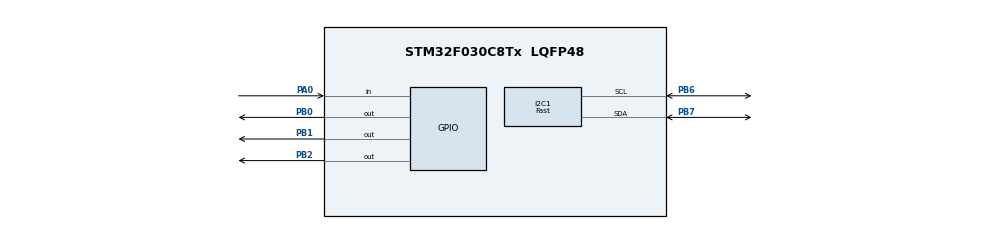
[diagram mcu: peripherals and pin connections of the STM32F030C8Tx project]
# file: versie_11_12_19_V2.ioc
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I2C1.I2C_Speed_Mode=I2C_Fast
I2C1.Timing=0x0000020B
Mcu.Family=STM32F0
Mcu.Name=STM32F030C8Tx
Mcu.Package=LQFP48
NVIC.TIM6_IRQn=true\:0\:0\:false\:false\:true\:true\:true
PA0.GPIO_PuPd=GPIO_PULLDOWN
PA0.Signal=GPIO_Input
PA13.Mode=Serial_Wire
PA13.Signal=SYS_SWDIO
PA14.Mode=Serial_Wire
PA14.Signal=SYS_SWCLK
PB0.GPIO_ModeDefaultOutputPP=GPIO_MODE_OUTPUT_PP
PB0.GPIO_PuPd=GPIO_NOPULL
PB0.GPIO_Speed=GPIO_SPEED_FREQ_LOW
PB0.PinState=GPIO_PIN_RESET
PB0.Signal=GPIO_Output
PB1.GPIO_ModeDefaultOutputPP=GPIO_MODE_OUTPUT_PP
PB1.GPIO_PuPd=GPIO_NOPULL
PB1.GPIO_Speed=GPIO_SPEED_FREQ_LOW
PB1.PinState=GPIO_PIN_RESET
PB1.Signal=GPIO_Output
PB2.GPIO_ModeDefaultOutputPP=GPIO_MODE_OUTPUT_PP
PB2.GPIO_PuPd=GPIO_NOPULL
PB2.GPIO_Speed=GPIO_SPEED_FREQ_LOW
PB2.PinState=GPIO_PIN_RESET
PB2.Signal=GPIO_Output
PB6.Mode=I2C
PB6.Signal=I2C1_SCL
PB7.Mode=I2C
PB7.Signal=I2C1_SDA
ProjectManager.HeapSize=0x200
ProjectManager.StackSize=0x400
ProjectManager.TargetToolchain=STM32CubeIDE
TIM6.Period=1000
TIM6.Prescaler=8000
VP_TIM6_VS_ClockSourceINT.Mode=Enable_Timer
board=custom

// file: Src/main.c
/* USER CODE BEGIN Header */
/**
  ******************************************************************************
  * @file           : main.c
  * @brief          : Main program body
  ******************************************************************************
  * @attention
  *
  * <h2><center>&copy; Copyright (c) 2019 STMicroelectronics.
  * All rights reserved.</center></h2>
  *
  * This software component is licensed by ST under BSD 3-Clause license,
  * the "License"; You may not use this file except in compliance with the
  * License. You may obtain a copy of the License at:
  *                        opensource.org/licenses/BSD-3-Clause
  *
  ******************************************************************************
  */
/* USER CODE END Header */

#include "main.h"

/* USER CODE BEGIN Includes */
#define true  1
#define false 0

#define init  0
#define sending 1
#define sended  2
#define running 3

int status;
/* USER CODE END Includes */

I2C_HandleTypeDef hi2c1;

TIM_HandleTypeDef htim6;

void SystemClock_Config(void);
static void MX_GPIO_Init(void);
static void MX_I2C1_Init(void);
static void MX_TIM6_Init(void);

int main(void)
{

  /* MCU Configuration--------------------------------------------------------*/

  /* Reset of all peripherals, Initializes the Flash interface and the Systick. */
  HAL_Init();

  /* Configure the system clock */
  SystemClock_Config();

  /* Initialize all configured peripherals */
  MX_GPIO_Init();
  MX_I2C1_Init();
  MX_TIM6_Init();
  /* USER CODE BEGIN 2 */
  HAL_GPIO_WritePin(GPIOB, GPIO_PIN_0, 1);
  HAL_GPIO_WritePin(GPIOB, GPIO_PIN_1, 1);
  HAL_GPIO_WritePin(GPIOB, GPIO_PIN_2, 1);
  HAL_TIM_Base_Start_IT(&htim6);
  /* USER CODE END 2 */

  /* Infinite loop */
  while (1)
    {
  	  status=init;
  	  while(status==init){
  		  updateLED();
  		  if(HAL_I2C_IsDeviceReady(&hi2c1, 0xFF, 10, 100)==HAL_OK){
  			  HAL_TIM_Base_Start(&htim6);
  			  status=running;
  		  }

  		HAL_GPIO_WritePin(GPIOB, GPIO_PIN_0, true); 				//blauwe led uitzetten
  		HAL_GPIO_WritePin(GPIOB, GPIO_PIN_1, false); 				//groene led uitzetten
  		HAL_GPIO_WritePin(GPIOB, GPIO_PIN_2, false); 				//rode led uitzetten
  		HAL_Delay(100);
  	  }

  	HAL_Delay(1000);
  	status=running;
  	updateLED();

    }
}

void updateLED(void){

	switch(status){
	case init:
		HAL_GPIO_WritePin(GPIOB, GPIO_PIN_0, true); 				//blauwe led aanzetten
		HAL_GPIO_WritePin(GPIOB, GPIO_PIN_1, false); 				//groene led uitzetten
		HAL_GPIO_WritePin(GPIOB, GPIO_PIN_2, false); 				//rode led uitzetten
		break;
	case sending:
		HAL_GPIO_WritePin(GPIOB, GPIO_PIN_0, false); 				//blauwe led uitzetten
		HAL_GPIO_WritePin(GPIOB, GPIO_PIN_1, false); 				//groene led uitzetten
		HAL_GPIO_WritePin(GPIOB, GPIO_PIN_2, true); 				//rode led aanzetten
		break;
	case sended:
		HAL_GPIO_WritePin(GPIOB, GPIO_PIN_0, false); 				//blauwe led uitzetten
		HAL_GPIO_WritePin(GPIOB, GPIO_PIN_1, true); 				//groene led aanzetten
		HAL_GPIO_WritePin(GPIOB, GPIO_PIN_2, true); 				//rode led aanzetten
		break;
	case running:
		HAL_GPIO_WritePin(GPIOB, GPIO_PIN_0, false); 				//blauwe led uitzetten
		HAL_GPIO_WritePin(GPIOB, GPIO_PIN_1, true); 				//groene led aanzetten
		HAL_GPIO_WritePin(GPIOB, GPIO_PIN_2, false); 				//rode led uitzetten
		break;
	}
}

void SystemClock_Config(void)
{
  RCC_OscInitTypeDef RCC_OscInitStruct = {0};
  RCC_ClkInitTypeDef RCC_ClkInitStruct = {0};
  RCC_PeriphCLKInitTypeDef PeriphClkInit = {0};

  /** Initializes the CPU, AHB and APB busses clocks
  */
  RCC_OscInitStruct.OscillatorType = RCC_OSCILLATORTYPE_HSI;
  RCC_OscInitStruct.HSIState = RCC_HSI_ON;
  RCC_OscInitStruct.HSICalibrationValue = RCC_HSICALIBRATION_DEFAULT;
  RCC_OscInitStruct.PLL.PLLState = RCC_PLL_NONE;
  if (HAL_RCC_OscConfig(&RCC_OscInitStruct) != HAL_OK)
  {
    Error_Handler();
  }
  /** Initializes the CPU, AHB and APB busses clocks
  */
  RCC_ClkInitStruct.ClockType = RCC_CLOCKTYPE_HCLK|RCC_CLOCKTYPE_SYSCLK
                              |RCC_CLOCKTYPE_PCLK1;
  RCC_ClkInitStruct.SYSCLKSource = RCC_SYSCLKSOURCE_HSI;
  RCC_ClkInitStruct.AHBCLKDivider = RCC_SYSCLK_DIV1;
  RCC_ClkInitStruct.APB1CLKDivider = RCC_HCLK_DIV1;

  if (HAL_RCC_ClockConfig(&RCC_ClkInitStruct, FLASH_LATENCY_0) != HAL_OK)
  {
    Error_Handler();
  }
  PeriphClkInit.PeriphClockSelection = RCC_PERIPHCLK_I2C1;
  PeriphClkInit.I2c1ClockSelection = RCC_I2C1CLKSOURCE_HSI;
  if (HAL_RCCEx_PeriphCLKConfig(&PeriphClkInit) != HAL_OK)
  {
    Error_Handler();
  }
}

static void MX_I2C1_Init(void)
{

  hi2c1.Instance = I2C1;
  hi2c1.Init.Timing = 0x0000020B;
  hi2c1.Init.OwnAddress1 = 0;
  hi2c1.Init.AddressingMode = I2C_ADDRESSINGMODE_7BIT;
  hi2c1.Init.DualAddressMode = I2C_DUALADDRESS_DISABLE;
  hi2c1.Init.OwnAddress2 = 0;
  hi2c1.Init.OwnAddress2Masks = I2C_OA2_NOMASK;
  hi2c1.Init.GeneralCallMode = I2C_GENERALCALL_DISABLE;
  hi2c1.Init.NoStretchMode = I2C_NOSTRETCH_DISABLE;
  if (HAL_I2C_Init(&hi2c1) != HAL_OK)
  {
    Error_Handler();
  }
  /** Configure Analogue filter
  */
  if (HAL_I2CEx_ConfigAnalogFilter(&hi2c1, I2C_ANALOGFILTER_ENABLE) != HAL_OK)
  {
    Error_Handler();
  }
  /** Configure Digital filter
  */
  if (HAL_I2CEx_ConfigDigitalFilter(&hi2c1, 0) != HAL_OK)
  {
    Error_Handler();
  }

}

static void MX_TIM6_Init(void)
{

  htim6.Instance = TIM6;
  htim6.Init.Prescaler = 8000;
  htim6.Init.CounterMode = TIM_COUNTERMODE_UP;
  htim6.Init.Period = 1000;
  htim6.Init.AutoReloadPreload = TIM_AUTORELOAD_PRELOAD_DISABLE;
  if (HAL_TIM_Base_Init(&htim6) != HAL_OK)
  {
    Error_Handler();
  }

}
void HAL_TIM_PeriodElapsedCallback(TIM_HandleTypeDef *htim){
	if(htim->Instance==TIM6){
		  if(HAL_GPIO_ReadPin(GPIOA, GPIO_PIN_0)!=GPIO_PIN_SET){
			  HAL_GPIO_WritePin(GPIOB, GPIO_PIN_1, 0);
		  }else{
			  HAL_GPIO_WritePin(GPIOB, GPIO_PIN_1, 1);
		  }
	}
}
static void MX_GPIO_Init(void)
{
  GPIO_InitTypeDef GPIO_InitStruct = {0};

  /* GPIO Ports Clock Enable */
  __HAL_RCC_GPIOA_CLK_ENABLE();
  __HAL_RCC_GPIOB_CLK_ENABLE();

  /*Configure GPIO pin Output Level */
  HAL_GPIO_WritePin(GPIOB, GPIO_PIN_0|GPIO_PIN_1|GPIO_PIN_2, GPIO_PIN_RESET);

  /*Configure GPIO pin : PA0 */
  GPIO_InitStruct.Pin = GPIO_PIN_0;
  GPIO_InitStruct.Mode = GPIO_MODE_INPUT;
  GPIO_InitStruct.Pull = GPIO_PULLDOWN;
  HAL_GPIO_Init(GPIOA, &GPIO_InitStruct);

  /*Configure GPIO pins : PB0 PB1 PB2 */
  GPIO_InitStruct.Pin = GPIO_PIN_0|GPIO_PIN_1|GPIO_PIN_2;
  GPIO_InitStruct.Mode = GPIO_MODE_OUTPUT_PP;
  GPIO_InitStruct.Pull = GPIO_NOPULL;
  GPIO_InitStruct.Speed = GPIO_SPEED_FREQ_LOW;
  HAL_GPIO_Init(GPIOB, &GPIO_InitStruct);

}

void Error_Handler(void)
{
}

/************************ (C) COPYRIGHT STMicroelectronics *****END OF FILE****/
